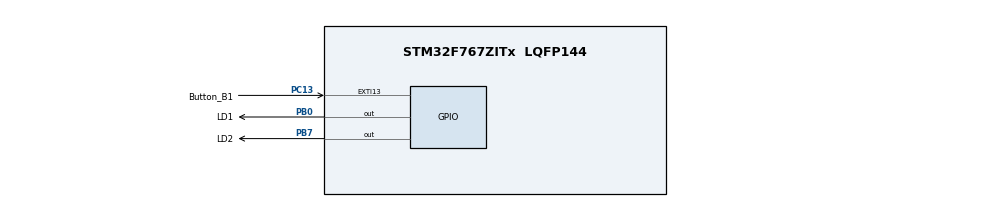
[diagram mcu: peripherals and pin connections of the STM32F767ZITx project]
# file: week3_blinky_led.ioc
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Mcu.Family=STM32F7
Mcu.Name=STM32F767ZITx
Mcu.Package=LQFP144
NVIC.EXTI15_10_IRQn=true\:0\:0\:false\:false\:true\:true\:true\:true
NVIC.PriorityGroup=NVIC_PRIORITYGROUP_4
NVIC.TIM8_TRG_COM_TIM14_IRQn=true\:0\:0\:false\:false\:true\:true\:true\:true
PB0.GPIO_Label=LD1
PB0.Signal=GPIO_Output
PB7.GPIO_Label=LD2
PB7.Signal=GPIO_Output
PC13.GPIO_Label=Button_B1
PC13.GPIO_ModeDefaultEXTI=GPIO_MODE_IT_RISING
PC13.Signal=GPXTI13
ProjectManager.HeapSize=0x200
ProjectManager.StackSize=0x400
ProjectManager.TargetToolchain=STM32CubeIDE
RCC.HSE_VALUE=25000000
RCC.HSI_VALUE=16000000
RCC.LSE_VALUE=32768
RCC.USBFreq_Value=96000000
RCC.VCOOutputFreq_Value=192000000
TIM14.Channel=TIM_CHANNEL_1
TIM14.ClockDivision=TIM_CLOCKDIVISION_DIV2
TIM14.Prescaler=16
VP_TIM14_VS_ClockSourceINT.Mode=Enable_Timer
VP_TIM14_VS_no_output1.Mode=Output Compare1 No Output
board=custom

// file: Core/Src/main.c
/* USER CODE BEGIN Header */
/**
  ******************************************************************************
  * @file           : main.c
  * @brief          : Main program body
  ******************************************************************************
  * @attention
  *
  * Copyright (c) 2023 STMicroelectronics.
  * All rights reserved.
  *
  * This software is licensed under terms that can be found in the LICENSE file
  * in the root directory of this software component.
  * If no LICENSE file comes with this software, it is provided AS-IS.
  *
  ******************************************************************************
  */
/* USER CODE END Header */
#include "main.h"
#include "tim.h"
#include "gpio.h"

void SystemClock_Config(void);
/* USER CODE BEGIN PFP */
static uint32_t blinky_flag = 0;
static uint32_t button_flag = 0;
/* USER CODE END PFP */

/* USER CODE BEGIN 0 */
void HAL_TIM_PeriodElapsedCallback(TIM_HandleTypeDef *htim)
{
	blinky_flag = 1;
}

void HAL_GPIO_EXTI_Callback(uint16_t GPIO_Pin)
{
	button_flag = 1;
	HAL_NVIC_DisableIRQ(EXTI15_10_IRQn);
}
/* USER CODE END 0 */

int main(void)
{

  /* MCU Configuration--------------------------------------------------------*/

  /* Reset of all peripherals, Initializes the Flash interface and the Systick. */
  HAL_Init();

  /* Configure the system clock */
  SystemClock_Config();

  /* Initialize all configured peripherals */
  MX_GPIO_Init();
  MX_TIM14_Init();
  /* USER CODE BEGIN 2 */
  HAL_TIM_Base_Start_IT(&htim14);
  /* USER CODE END 2 */

  /* Infinite loop */
  while (1)
  {

    /* USER CODE BEGIN 3 */
	if (blinky_flag)
	{
		HAL_GPIO_TogglePin(GPIOB, LD1_Pin);
		blinky_flag = 0;
	}

	if (button_flag)
	{
		HAL_GPIO_TogglePin(GPIOB, LD2_Pin);
		button_flag = 0;
		HAL_NVIC_EnableIRQ(EXTI15_10_IRQn);
	}
  }
  /* USER CODE END 3 */
}

void SystemClock_Config(void)
{
  RCC_OscInitTypeDef RCC_OscInitStruct = {0};
  RCC_ClkInitTypeDef RCC_ClkInitStruct = {0};

  /** Configure the main internal regulator output voltage
  */
  __HAL_RCC_PWR_CLK_ENABLE();
  __HAL_PWR_VOLTAGESCALING_CONFIG(PWR_REGULATOR_VOLTAGE_SCALE3);

  /** Initializes the RCC Oscillators according to the specified parameters
  * in the RCC_OscInitTypeDef structure.
  */
  RCC_OscInitStruct.OscillatorType = RCC_OSCILLATORTYPE_HSI;
  RCC_OscInitStruct.HSIState = RCC_HSI_ON;
  RCC_OscInitStruct.HSICalibrationValue = RCC_HSICALIBRATION_DEFAULT;
  RCC_OscInitStruct.PLL.PLLState = RCC_PLL_NONE;
  if (HAL_RCC_OscConfig(&RCC_OscInitStruct) != HAL_OK)
  {
    Error_Handler();
  }

  /** Initializes the CPU, AHB and APB buses clocks
  */
  RCC_ClkInitStruct.ClockType = RCC_CLOCKTYPE_HCLK|RCC_CLOCKTYPE_SYSCLK
                              |RCC_CLOCKTYPE_PCLK1|RCC_CLOCKTYPE_PCLK2;
  RCC_ClkInitStruct.SYSCLKSource = RCC_SYSCLKSOURCE_HSI;
  RCC_ClkInitStruct.AHBCLKDivider = RCC_SYSCLK_DIV1;
  RCC_ClkInitStruct.APB1CLKDivider = RCC_HCLK_DIV1;
  RCC_ClkInitStruct.APB2CLKDivider = RCC_HCLK_DIV1;

  if (HAL_RCC_ClockConfig(&RCC_ClkInitStruct, FLASH_LATENCY_0) != HAL_OK)
  {
    Error_Handler();
  }
}

void Error_Handler(void)
{
  __disable_irq();
  while (1)
  {
  }
}
